# nrf54lv10a_enga_application register map
Vendor: Nordic Semiconductor; Series: nrf54l; File version: 1
CPU: CM33 r0p4, little endian, MPU, FPU, 3 interrupt priority bits, 270 interrupts, 4 SAU regions
Registers are 32-bit, read-write, reset 0x0 unless marked. A register's access mark holds for its fields unless they carry their own. Offsets are from the block's base; [hi:lo] are bit positions; lines under a group give offsets from that group; {n}, {i} and the like mark numbered series; 'fields as' and 'values as' point back to an identical list.

## GLOBAL_SAADC_NS — Analog to Digital Converter 0
Base 0x400D5000
Same registers: GLOBAL_SAADC_S 0x500D5000
0x00 TASKS_START wo — Start the ADC and prepare the result buffer in RAM
  [0] TASKS_START
    1=Trigger task
0x04 TASKS_SAMPLE wo — Take one ADC sample, if scan is enabled all channels are sampled. This task requires that SAADC has started, i.e. EVENTS_STARTED was set and EVENTS_STOPPED was not.
  [0] TASKS_SAMPLE
    1=Trigger task
0x08 TASKS_STOP wo — Stop the ADC and terminate any on-going conversion
  [0] TASKS_STOP
    1=Trigger task
0x0C TASKS_CALIBRATEOFFSET wo — Starts offset auto-calibration
  [0] TASKS_CALIBRATEOFFSET
    1=Trigger task
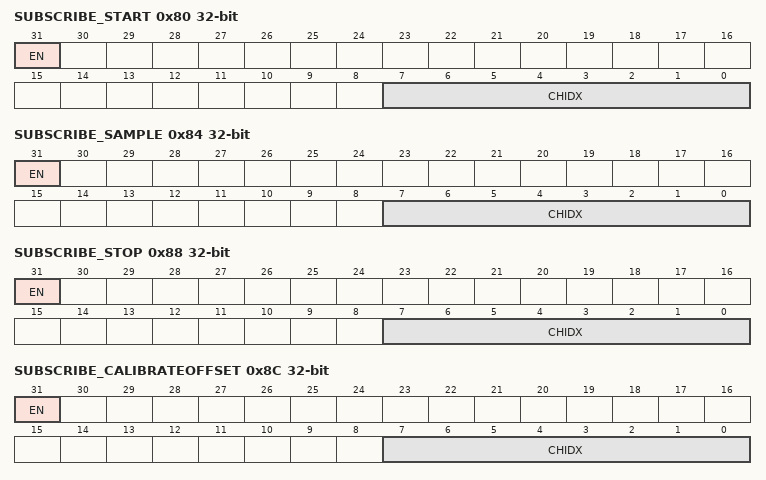
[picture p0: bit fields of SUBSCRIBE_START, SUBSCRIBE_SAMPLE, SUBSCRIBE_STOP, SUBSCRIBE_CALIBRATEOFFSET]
0x80 SUBSCRIBE_START — Subscribe configuration for task START
  [31] EN
    0=Disabled (Disable subscription); 1=Enabled (Enable subscription)
  [7:0] CHIDX — DPPI channel that task START will subscribe to
0x84 SUBSCRIBE_SAMPLE — Subscribe configuration for task SAMPLE
  [31] EN
    values as SUBSCRIBE_START.EN
  [7:0] CHIDX — DPPI channel that task SAMPLE will subscribe to
0x88 SUBSCRIBE_STOP — Subscribe configuration for task STOP
  [31] EN
    values as SUBSCRIBE_START.EN
  [7:0] CHIDX — DPPI channel that task STOP will subscribe to
0x8C SUBSCRIBE_CALIBRATEOFFSET — Subscribe configuration for task CALIBRATEOFFSET
  [31] EN
    values as SUBSCRIBE_START.EN
  [7:0] CHIDX — DPPI channel that task CALIBRATEOFFSET will subscribe to
0x100 EVENTS_STARTED — The ADC has started
  [0] EVENTS_STARTED
    0=NotGenerated (Event not generated); 1=Generated (Event generated)
0x104 EVENTS_END — The ADC has filled up the Result buffer
  [0] EVENTS_END
    values as EVENTS_STARTED.EVENTS_STARTED
0x108 EVENTS_DONE — A conversion task has been completed. Depending on the mode, multiple conversions might be needed for a result to be transferred to RAM.
  [0] EVENTS_DONE
    values as EVENTS_STARTED.EVENTS_STARTED
0x10C EVENTS_RESULTDONE — A result is ready to get transferred to RAM.
  [0] EVENTS_RESULTDONE
    values as EVENTS_STARTED.EVENTS_STARTED
0x110 EVENTS_CALIBRATEDONE — Calibration is complete
  [0] EVENTS_CALIBRATEDONE
    values as EVENTS_STARTED.EVENTS_STARTED
0x114 EVENTS_STOPPED — The ADC has stopped
  [0] EVENTS_STOPPED
    values as EVENTS_STARTED.EVENTS_STARTED
{0x118+8i} EVENTS_CH[{i}] (i=0..3) group — Peripheral events.
  0x00 LIMITH — Description cluster: Last results is equal or above CH[n].LIMIT.HIGH
    [0] LIMITH — Last results is equal or above CH[n].LIMIT.HIGH
      values as EVENTS_STARTED.EVENTS_STARTED
  0x04 LIMITL — Description cluster: Last results is equal or below CH[n].LIMIT.LOW
    [0] LIMITL — Last results is equal or below CH[n].LIMIT.LOW
      values as EVENTS_STARTED.EVENTS_STARTED
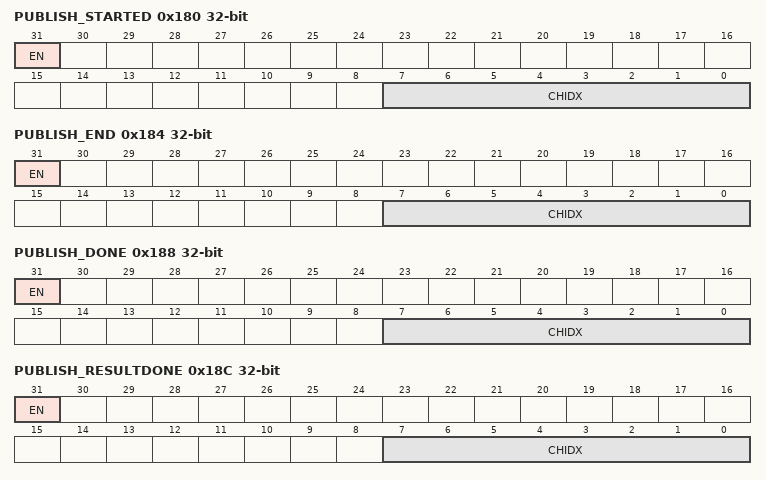
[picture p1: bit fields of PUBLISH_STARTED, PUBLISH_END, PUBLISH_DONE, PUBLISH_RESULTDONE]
0x180 PUBLISH_STARTED — Publish configuration for event STARTED
  [31] EN
    0=Disabled (Disable publishing); 1=Enabled (Enable publishing)
  [7:0] CHIDX — DPPI channel that event STARTED will publish to
0x184 PUBLISH_END — Publish configuration for event END
  [31] EN
    values as PUBLISH_STARTED.EN
  [7:0] CHIDX — DPPI channel that event END will publish to
0x188 PUBLISH_DONE — Publish configuration for event DONE
  [31] EN
    values as PUBLISH_STARTED.EN
  [7:0] CHIDX — DPPI channel that event DONE will publish to
0x18C PUBLISH_RESULTDONE — Publish configuration for event RESULTDONE
  [31] EN
    values as PUBLISH_STARTED.EN
  [7:0] CHIDX — DPPI channel that event RESULTDONE will publish to
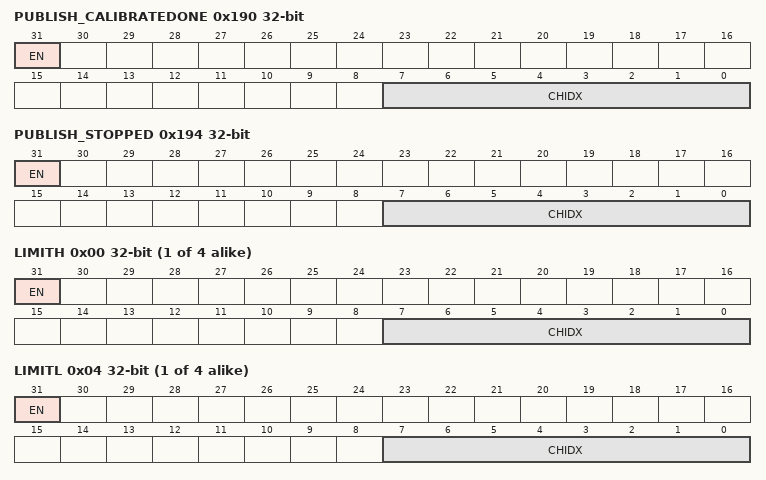
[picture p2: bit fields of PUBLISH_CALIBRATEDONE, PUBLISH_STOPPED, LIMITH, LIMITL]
0x190 PUBLISH_CALIBRATEDONE — Publish configuration for event CALIBRATEDONE
  [31] EN
    values as PUBLISH_STARTED.EN
  [7:0] CHIDX — DPPI channel that event CALIBRATEDONE will publish to
0x194 PUBLISH_STOPPED — Publish configuration for event STOPPED
  [31] EN
    values as PUBLISH_STARTED.EN
  [7:0] CHIDX — DPPI channel that event STOPPED will publish to
{0x198+8i} PUBLISH_CH[{i}] (i=0..3) group — Publish configuration for events
  0x00 LIMITH — Description cluster: Publish configuration for event CH[n].LIMITH
    [31] EN
      values as PUBLISH_STARTED.EN
    [7:0] CHIDX — DPPI channel that event CH[n].LIMITH will publish to
  0x04 LIMITL — Description cluster: Publish configuration for event CH[n].LIMITL
    [31] EN
      values as PUBLISH_STARTED.EN
    [7:0] CHIDX — DPPI channel that event CH[n].LIMITL will publish to
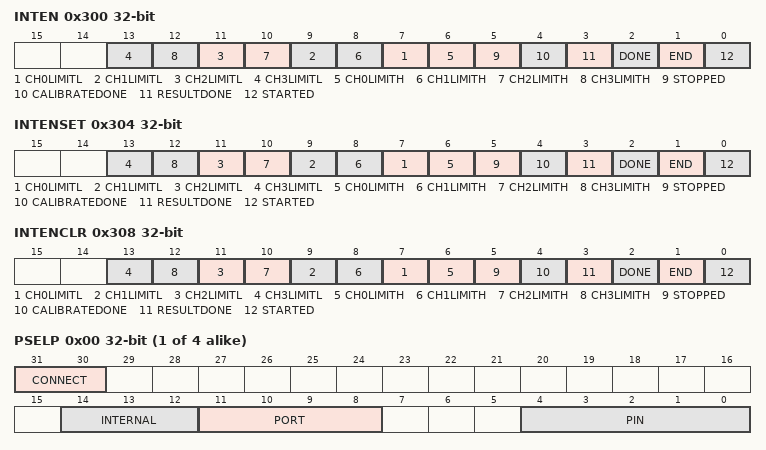
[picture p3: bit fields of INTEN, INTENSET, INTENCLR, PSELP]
0x300 INTEN — Enable or disable interrupt
  [all] fields
    0=Disabled; 1=Enabled
  [2n+7] CH{n}LIMITL (n=0..3) — Enable or disable interrupt for event CH{n}LIMITL
  [2n+6] CH{n}LIMITH (n=0..3) — Enable or disable interrupt for event CH{n}LIMITH
  [5] STOPPED — Enable or disable interrupt for event STOPPED
  [4] CALIBRATEDONE — Enable or disable interrupt for event CALIBRATEDONE
  [3] RESULTDONE — Enable or disable interrupt for event RESULTDONE
  [2] DONE — Enable or disable interrupt for event DONE
  [1] END — Enable or disable interrupt for event END
  [0] STARTED — Enable or disable interrupt for event STARTED
0x304 INTENSET — Enable interrupt
  [all] fields
    on read: 0=Disabled (Read: Disabled); 1=Enabled (Read: Enabled) | on write: 1=Set (Enable)
  [2n+7] CH{n}LIMITL write-1-sets (n=0..3) — Write '1' to enable interrupt for event CH{n}LIMITL
  [2n+6] CH{n}LIMITH write-1-sets (n=0..3) — Write '1' to enable interrupt for event CH{n}LIMITH
  [5] STOPPED write-1-sets — Write '1' to enable interrupt for event STOPPED
  [4] CALIBRATEDONE write-1-sets — Write '1' to enable interrupt for event CALIBRATEDONE
  [3] RESULTDONE write-1-sets — Write '1' to enable interrupt for event RESULTDONE
  [2] DONE write-1-sets — Write '1' to enable interrupt for event DONE
  [1] END write-1-sets — Write '1' to enable interrupt for event END
  [0] STARTED write-1-sets — Write '1' to enable interrupt for event STARTED
0x308 INTENCLR — Disable interrupt
  [all] fields
    on read: 0=Disabled (Read: Disabled); 1=Enabled (Read: Enabled) | on write: 1=Clear (Disable)
  [2n+7] CH{n}LIMITL write-1-clears (n=0..3) — Write '1' to disable interrupt for event CH{n}LIMITL
  [2n+6] CH{n}LIMITH write-1-clears (n=0..3) — Write '1' to disable interrupt for event CH{n}LIMITH
  [5] STOPPED write-1-clears — Write '1' to disable interrupt for event STOPPED
  [4] CALIBRATEDONE write-1-clears — Write '1' to disable interrupt for event CALIBRATEDONE
  [3] RESULTDONE write-1-clears — Write '1' to disable interrupt for event RESULTDONE
  [2] DONE write-1-clears — Write '1' to disable interrupt for event DONE
  [1] END write-1-clears — Write '1' to disable interrupt for event END
  [0] STARTED write-1-clears — Write '1' to disable interrupt for event STARTED
0x400 STATUS ro
  [0] STATUS
    0=Ready (ADC is ready. No on-going conversion.); 1=Busy (ADC is busy. Single conversion in progress.)
0x500 ENABLE — Enable or disable ADC
  [0] ENABLE
    0=Disabled (Disable ADC); 1=Enabled (Enable ADC)
{0x510+0x10*i} CH[{i}] (i=0..3) group — Unspecified
  0x00 PSELP — Description cluster: Input positive pin selection for CH[m]
    [31:30] CONNECT — Connection
      0=NC (Not connected); 1=AnalogInput (Select analog input); 2=Internal (Selects internal inputs.)
    [14:12] INTERNAL — Internal input selection for analog positive input when CH[m].PSELP.CONNECT = Internal
      0=Dvdd (Connected to the internal 0.9 V digital supply rail); 1=VddL (Connected to VDDL); 4=Vss (Unspecified)
    [11:8] PORT — GPIO port selection
    [4:0] PIN — GPIO pin selection.
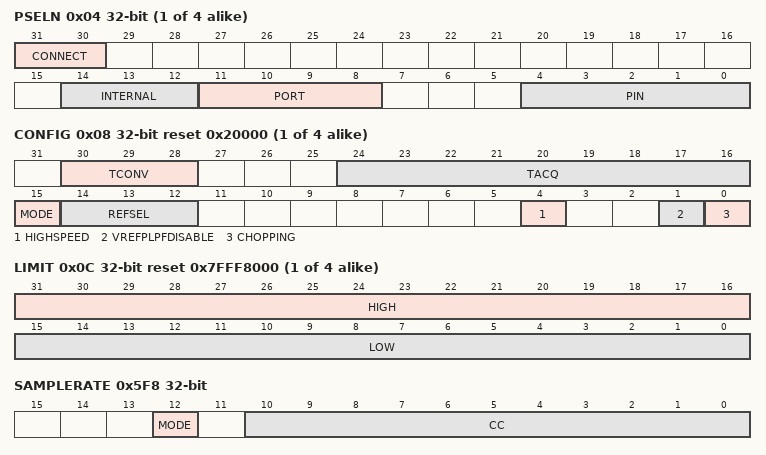
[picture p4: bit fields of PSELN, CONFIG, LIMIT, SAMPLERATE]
  0x04 PSELN — Description cluster: Input negative pin selection for CH[m]
    [31:30] CONNECT — Connection
      values as CH[0].PSELP.CONNECT
    [14:12] INTERNAL — Internal input selection for Analog negative input when CH[m].PSELN.CONNECT = Internal
      values as CH[0].PSELP.INTERNAL
    [11:8] PORT — GPIO Port selection
    [4:0] PIN — GPIO pin selection.
  0x08 CONFIG reset 0x20000 — Description cluster: Input configuration for CH[m]
    [30:28] TCONV — Conversion time. Resulting conversion time is ((TCONV+1) x 250 ns)
    [24:16] TACQ — Acquisition time, the time the ADC uses to sample the input voltage. Resulting acquistion time is ((TACQ+1) x 125 ns)
    [15] MODE — Enable differential mode
      0=SE (Single ended, PSELN will be ignored, negative input to ADC shorted to GND); 1=Differential
    [14:12] REFSEL — Reference control
      0=Internal 1.3 V reference; 1=External reference voltage; 2=VddL (Reference given at VDDL)
    [4] HIGHSPEED — Enable high speed inputs for the ADC, allowing the highest sampling bandwidth
      0=Disabled (High speed inputs are disabled); 1=Enabled (High speed inputs are enabled)
    [1] VREFPLPFDISABLE — Disable the internal low pass filter for the reference voltage
      1=Disabled (The internal low pass filter for the reference voltage is disabled (reference voltage is unfiltered and has faster settling time)); 0=Enabled (The internal low pass filter for the reference voltage is enabled (reference voltage is filtered))
    [0] CHOPPING — Enable chopping
      0=Disabled (Chopping is disabled); 1=Enabled (Chopping is enabled)
  0x0C LIMIT reset 0x7FFF8000 — Description cluster: High/low limits for event monitoring a channel
    [31:16] HIGH — High level limit
    [15:0] LOW — Low level limit
0x5E8 BURST — Enable burst mode
  [0] BURST
    0=Disabled (Burst mode is disabled (normal operation)); 1=Enabled (Burst mode is enabled. SAADC takes 2^OVERSAMPLE number of samples and sends the average to Data RAM.)
0x5F0 RESOLUTION reset 0x1 — Resolution configuration
  [2:0] VAL — Set the resolution
    0=8bit; 1=10bit; 2=12bit; 3=14bit
0x5F4 OVERSAMPLE — Oversampling configuration. OVERSAMPLE should not be combined with SCAN. The RESOLUTION is applied before averaging, thus for high OVERSAMPLE a higher RESOLUTION should be used.
  [3:0] OVERSAMPLE — Oversample control
    0=Bypass oversampling; 1=Over2x (Oversample 2x); 2=Over4x (Oversample 4x); 3=Over8x (Oversample 8x); 4=Over16x (Oversample 16x); 5=Over32x (Oversample 32x); 6=Over64x (Oversample 64x); 7=Over128x (Oversample 128x); 8=Over256x (Oversample 256x)
0x5F8 SAMPLERATE — Controls normal or continuous sample rate
  [12] MODE — Select mode for sample rate control
    0=Task (Rate is controlled from SAMPLE task); 1=Timers (Rate is controlled from local timer (use CC to control the rate))
  [10:0] CC — Capture and compare value. Sample rate is 16 MHz/CC
0x628 RESULT group — RESULT EasyDMA channel
  0x04 PTR — Data pointer
    [15:0] PTR
  0x08 MAXCNT — Maximum number of buffer bytes to transfer
    [14:0] MAXCNT
  0x0C AMOUNT ro — Number of buffer bytes transferred since last START, updated after the END or STOPPED events
    [14:0] AMOUNT — Number of buffer bytes transferred since last START, updated after the END or STOPPED events.
  0x10 CURRENTAMOUNT ro — Number of buffer bytes transferred since last START, continuously updated
    [14:0] AMOUNT — Number of buffer bytes transferred since last START, continuously updated.
